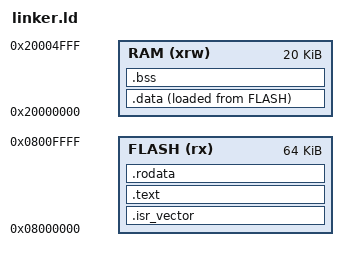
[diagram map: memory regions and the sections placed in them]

/* 地址符号常量: 
 * + _estack
 * + _sidata
 * + _sdata, _edata
 * + _sbss, _ebss
**/

MEMORY {
    FLASH (rx) : ORIGIN = 0x08000000, LENGTH = 64K
    RAM (xrw)  : ORIGIN = 0x20000000, LENGTH = 20K
}

/* 入口函数; 复位中断处理函数 */
ENTRY(Reset_Handler)

_estack = ORIGIN(RAM) + LENGTH(RAM);

SECTIONS {
    /* 中断向量表 */
    .isr_vector : {
        . = ALIGN(4);
        KEEP(*(.isr_vector))
        . = ALIGN(4);
    } >FLASH

    /* TODO 自动填充或避免越界 */

    /* 代码段 */
    .text : {
        . = ALIGN(4);
        *(.text)
        *(.text*)
        *(.glue_7)
        *(.glue_7t)
        *(.eh_frame)
        . = ALIGN(4);
    } >FLASH

    /* 只读数据段 */
    .rodata : {
        . = ALIGN(4);
        *(.rodata)
        *(.rodata*)
        . = ALIGN(4);
    } >FLASH
    _sidata = LOADADDR(.data);

    /* 全局变量; 需要在启动文件中映射 */
    .data : {
        . = ALIGN(4);
        _sdata = .;
        *(.data)
        *(.data*)
        . = ALIGN(4);
        _edata = .;
    } >RAM AT>FLASH

    /* 全局变量; 可选在启动文件中置零 */
    .bss : {
        _sbss = .;
        *(.bss)
        *(.bss*)
        . = ALIGN(4);
        _ebss = .;
    } >RAM
}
